# platform_designer_hps_system_hps_0_hps register map
Vendor: default_vendor.com; File version: 0.0
Registers are 32-bit, read-write, reset 0x0 unless marked. A register's access mark holds for its fields unless they carry their own. Offsets are from the block's base; [hi:lo] are bit positions; {n}, {i} and the like mark numbered series; 'fields as' and 'values as' point back to an identical list.

## spis0 — Registers in the SPI Slave module
Base 0xFFE02000
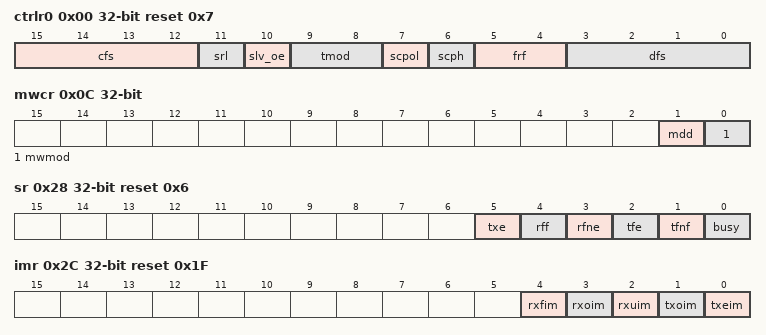
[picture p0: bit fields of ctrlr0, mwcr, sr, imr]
0x00 ctrlr0 reset 0x7 — This register controls the serial data transfer. It is impossible to write to this register when the SPI Slave is enabled. The SPI Slave is enabled and disabled by writing to the SPIENR register.
  [15:12] cfs — Selects the length of the control word for the Microwire frame format. The length (in bits) is the value of this field plus 1.
  [11] srl — Used for testing purposes only. When internally active, connects the transmit shift register output to the receive shift register input.
    0=normmode; 1=testmode
  [10] slv_oe — This bit enables or disables the setting of the spis0_ssi_oe_n output from the SPI Slave. When SLV_OE = 1, the spis0_ssi_oe_n output can never be active. When the spis0_ssi_oe_n output controls the tri-state buffer on the txd output from the slave, a high impedance state is always present on the slave spis0_txd output when SLV_OE = 1. This is useful when the master transmits in broadcast mode (master transmits data to all slave devices). Only one slave may respond with data on the master spis0_rxd line. This bit is enabled after reset and must be disabled by software (when broadcast mode is used), if you do not want this device to respond with data.
    0=enabled; 1=disabled
  [9:8] tmod — Selects the mode of transfer for serial communication. This field does not affect the transfer duplicity. Only indicates whether the receive or transmit data are valid. In transmit-only mode, data received from the external device is not valid and is not stored in the receive FIFO memory; it is overwritten on the next transfer. In receive-only mode, transmitted data are not valid. After the first write to the transmit FIFO, the same word is retransmitted for the duration of the transfer. In transmit-and-receive mode, both transmit and receive data are valid. The transfer continues until the transmit FIFO is empty. Data received from the external device are stored into the receive FIFO memory
    0=txrx; 1=txonly; 2=rxonly
  [7] scpol — Valid when the frame format (FRF) is set to Motorola SPI. Used to select the polarity of the inactive serial clock, which is held inactive when the spi master is not actively transferring data on the serial bus.
    0=midbit; 1=startbit
  [6] scph — Valid when the frame format (FRF) is set to Motorola SPI. The serial clock phase selects the relationship of the serial clock with the slave select signal. When SCPH = 0, data are captured on the first edge of the serial clock. When SCPH = 1, the serial clock starts toggling one cycle after the slave select line is activated, and data are captured on the second edge of the serial clock.
    0=inactivelow; 1=inactivehigh
  [5:4] frf — Selects which serial protocol transfers the data.
    0=motspi; 1=tissp; 2=natmw
  [3:0] dfs — Selects the data frame length. When the data frame size is programmed to be less than 16 bits, the receive data are automatically right-justified by the receive logic, with the upper bits of the receiver FIFO zero-padded. You must right-justify transmit data before writing into the transmit FIFO. The transmit logic ignores the upper unused bits when transmitting the data.
    {v}=width{v+1}bit (v=3..9)
0x08 spienr — Enables and disables all SPI operations.
  [0] spi_en — When disabled, all serial transfers are halted immediately. Transmit and receive FIFO buffers are cleared when the device is disabled. It is impossible to program some of the SPI Slave control registers when enabled.
    0=disabled; 1=enabled
0x0C mwcr — This register controls the direction of the data word for the half-duplex Microwire serial protocol. It is impossible to write to this register when the SPI Slave is enabled. The SPI Slave is enabled and disabled by writing to the SPIENR register.
  [1] mdd — Defines the direction of the data word when the Microwire serial protocol is used.
    0=rxmode; 1=txmode
  [0] mwmod — Defines whether the Microwire transfer is sequential or non-sequential. When sequential mode is used, only one control word is needed to transmit or receive a block of data words. When non-sequential mode is used, there must be a control word for each data word that is transmitted or received.
    0=nonseq; 1=seq
0x18 txftlr — This register controls the threshold value for the transmit FIFO memory. It is impossible to write to this register when the SPI Slave is enabled. The SPI Slave is enabled and disabled by writing to the SPIENR register.
  [7:0] tft — Controls the level of entries (or below) at which the transmit FIFO controller triggers an interrupt. When the number of transmit FIFO entries is less than or equal to this value, the transmit FIFO empty interrupt is triggered.
0x1C rxftlr — This register controls the threshold value for the receive FIFO memory. It is impossible to write to this register when the SPI Slave is enabled. The SPI Slave is enabled and disabled by writing to the SPIENR register.
  [7:0] rft — Controls the level of entries (or above) at which the receive FIFO controller triggers an interrupt. When the number of receive FIFO entries is greater than or equal to this value + 1, the receive FIFO full interrupt is triggered.
0x20 txflr ro — This register contains the number of valid data entries in the transmit FIFO memory. Ranges from 0 to 256.
  [8:0] txtfl — Contains the number of valid data entries in the transmit FIFO.
0x24 rxflr ro — This register contains the number of valid data entriesin the receive FIFO memory. This register can be read at any time. Ranges from 0 to 256.
  [8:0] rxtfl — Contains the number of valid data entries in the receive FIFO.
0x28 sr ro reset 0x6 — Reports FIFO transfer status, and any transmission/reception errors that may have occurred. The status register may be read at any time. None of the bits in this register request an interrupt.
  [5] txe — Data from the previous transmission is resent on the txd line. This bit is cleared when read.
    0=noerror; 1=error
  [4] rff — Reports the status of receive FIFO Full
    0=notfull; 1=full
  [3] rfne — Reports the status of receive FIFO empty.
    0=empty; 1=notempty
  [2] tfe — Reports the status of transmit FIFO empty. This bit field does not request an interrupt.
    1=empty; 0=notempty
  [1] tfnf — Reports the status of the transmit FIFO.
    0=full; 1=notfull
  [0] busy — Reports the status of a serial transfer
    0=inactive; 1=active
0x2C imr reset 0x1F — This register masks or enables all interrupts generated by the SPI Slave.
  [all] fields
    0=masked; 1=enabled
  [4] rxfim — FIFO Full Mask.
  [3] rxoim — Overflow Mask.
  [2] rxuim — Underfow Mask
  [1] txoim — Overflow mask.
  [0] txeim — Empty mask.
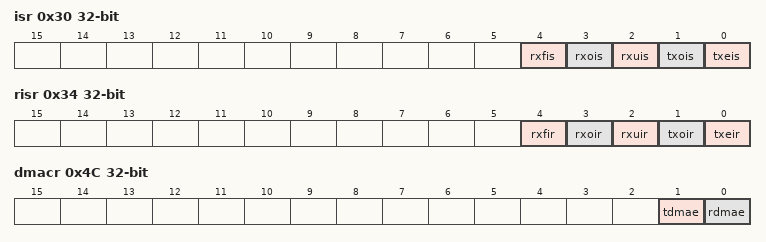
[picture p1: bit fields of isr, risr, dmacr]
0x30 isr ro — This register reports the status of the SPI Slave interrupts after they have been masked.
  [all] fields
    0=inactive; 1=active
  [4] rxfis — Full Status
  [3] rxois — Overflow Status.
  [2] rxuis — Underflow Status.
  [1] txois — Overflow Status.
  [0] txeis — Empty Status.
0x34 risr ro — This register reports the status of the SPI Slave interrupts prior to masking.
  [all] fields
    0=inactive; 1=active
  [4] rxfir — The interrupt is active or inactive prior to masking.
  [3] rxoir — The interrupt is active or inactive prior to masking.
  [2] rxuir — The interrupt is active or inactive prior to masking.
  [1] txoir — The interrupt is active or inactive prior to masking.
  [0] txeir — The interrupt is active or inactive prior to masking.
0x38 txoicr ro
  [0] txoicr — This register reflects the status of the interrupt. A read from this register clears the ssi_txo_intr interrupt; writing has no effect.
0x3C rxoicr ro
  [0] rxoicr — This register reflects the status of the interrupt. A read from this register clears the ssi_rxo_intr interrupt; writing has no effect.
0x40 rxuicr ro
  [0] rxuicr — This register reflects the status of the interrupt. A read from this register clears the ssi_rxu_intr interrupt; writing has no effect.
0x48 icr ro
  [0] icr — This register is set if any of the interrupts below are active. A read clears the ssi_txo_intr, ssi_rxu_intr, ssi_rxo_intr, and the ssi_mst_intr interrupts. Writing to this register has no effect.
0x4C dmacr — The register is used to enable the DMA Controller interface operation.
  [1] tdmae — This bit enables/disables the transmit FIFO DMA channel.
    0=disabled; 1=enabled
  [0] rdmae — This bit enables/disables the receive FIFO DMA channel
    0=disabled; 1=enabled
0x50 dmatdlr — Controls DMA Transmit FIFO Threshold
  [7:0] dmatdl — This bit field controls the level at which a DMA request is made by the transmit logic. It is equal to the watermark level; that is, the dma_tx_req signal is generated when the number of valid data entries in the transmit FIFO is equal to or below this field value, and TDMAE = 1.
0x54 dmardlr — Controls DMA Receive FIFO Threshold
  [7:0] dmardl — This bit field controls the level at which a DMA request is made by the receive logic. The watermark level = DMARDL+1; that is, dma_rx_req is generated when the number of valid data entries in the receive FIFO is equal to or above this field value + 1, and RDMAE=1.
0x58 idr ro reset 0x5510005 — This register stores a peripheral identification code
  [31:0] idr — This filed contains the peripherals identification code, 0x05510005.
0x5C spi_version_id reset 0x3332302A — This read-only register stores the specific SPI Slave component version.
  [31:0] spi_version_id — Contains the hex representation of the Synopsys component version. Consists of ASCII value for each number in the version.
0x60 dr — The data register is a 16-bit read/write buffer for the transmit/receive FIFOs. When the register is read, data in the receive FIFO buffer is accessed. When it is written to, data are moved into the transmit FIFO buffer; a write can occur only when SPI_EN = 1. FIFOs are reset when SPI_EN = 0.
  [15:0] dr — When writing to this register, you must right-justify the data. Read data are automatically right-justified. Read = Receive FIFO buffer Write = Transmit FIFO buffer

## spis1 — Registers in the SPI Slave module
Base 0xFFE03000
Registers as spis0; these are added or differ:
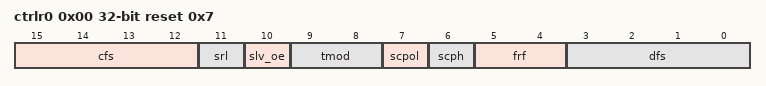
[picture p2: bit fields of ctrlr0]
0x00 ctrlr0 reset 0x7 — This register controls the serial data transfer. It is impossible to write to this register when the SPI Slave is enabled. The SPI Slave is enabled and disabled by writing to the SPIENR register.
  fields as spis0.ctrlr0
